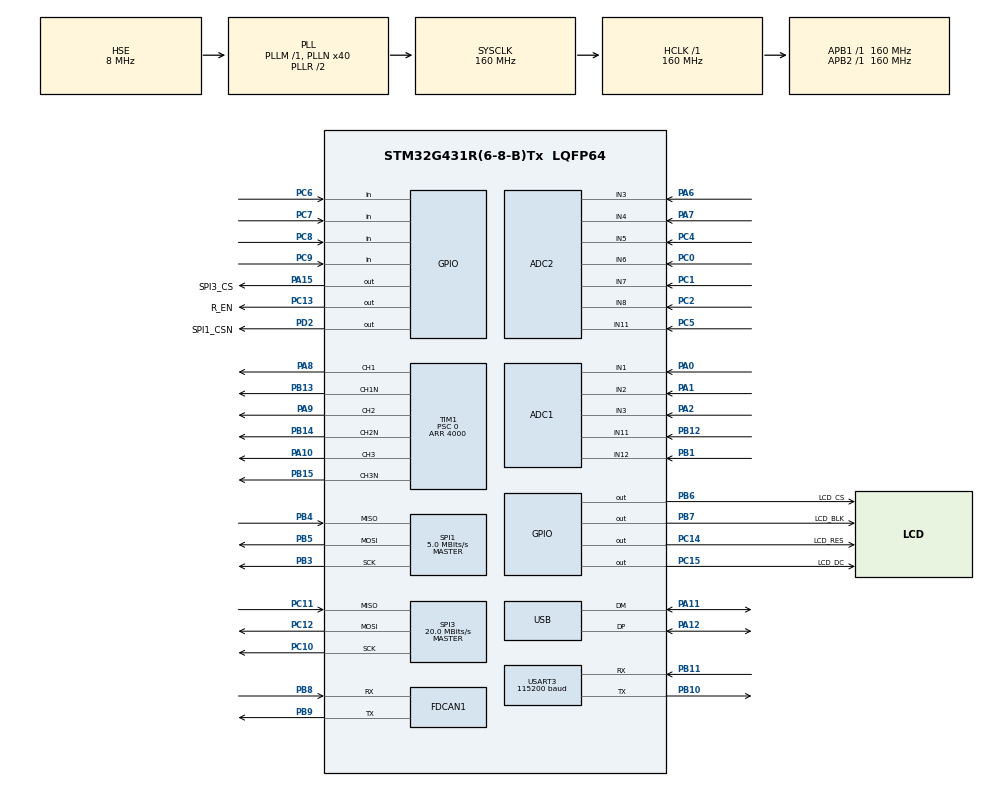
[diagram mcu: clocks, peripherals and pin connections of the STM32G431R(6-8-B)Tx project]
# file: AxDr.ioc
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ADC1.Channel-4\#ChannelRegularConversion=ADC_CHANNEL_11
ADC1.Channel-5\#ChannelRegularConversion=ADC_CHANNEL_12
ADC1.ContinuousConvMode=ENABLE
ADC1.DMAContinuousRequests=ENABLE
ADC1.EnableInjectedConversion=ENABLE
ADC1.EnableRegularConversion=ENABLE
ADC1.ExternalTrigInjecConv=ADC_EXTERNALTRIGINJEC_T1_CC4
ADC1.ExternalTrigInjecConvEdge=ADC_EXTERNALTRIGINJECCONV_EDGE_FALLING
ADC1.InjNumberOfConversion=3
ADC1.InjectedChannel-1\#ChannelInjectedConversion=ADC_CHANNEL_1
ADC1.InjectedChannel-2\#ChannelInjectedConversion=ADC_CHANNEL_2
ADC1.InjectedChannel-3\#ChannelInjectedConversion=ADC_CHANNEL_3
ADC1.InjectedOffsetNumber-1\#ChannelInjectedConversion=ADC_OFFSET_NONE
ADC1.InjectedOffsetNumber-2\#ChannelInjectedConversion=ADC_OFFSET_NONE
ADC1.InjectedOffsetNumber-3\#ChannelInjectedConversion=ADC_OFFSET_NONE
ADC1.InjectedRank-1\#ChannelInjectedConversion=1
ADC1.InjectedRank-2\#ChannelInjectedConversion=2
ADC1.InjectedRank-3\#ChannelInjectedConversion=3
ADC1.InjectedSamplingTime-1\#ChannelInjectedConversion=ADC_SAMPLETIME_47CYCLES_5
ADC1.InjectedSamplingTime-2\#ChannelInjectedConversion=ADC_SAMPLETIME_47CYCLES_5
ADC1.InjectedSamplingTime-3\#ChannelInjectedConversion=ADC_SAMPLETIME_47CYCLES_5
ADC1.NbrOfConversion=2
ADC1.NbrOfConversionFlag=1
ADC1.OffsetNumber-4\#ChannelRegularConversion=ADC_OFFSET_NONE
ADC1.OffsetNumber-5\#ChannelRegularConversion=ADC_OFFSET_NONE
ADC1.Rank-4\#ChannelRegularConversion=1
ADC1.Rank-5\#ChannelRegularConversion=2
ADC1.SamplingTime-4\#ChannelRegularConversion=ADC_SAMPLETIME_47CYCLES_5
ADC1.SamplingTime-5\#ChannelRegularConversion=ADC_SAMPLETIME_47CYCLES_5
ADC1.master=1
ADC2.Channel-11\#ChannelRegularConversion=ADC_CHANNEL_5
ADC2.Channel-12\#ChannelRegularConversion=ADC_CHANNEL_6
ADC2.Channel-13\#ChannelRegularConversion=ADC_CHANNEL_7
ADC2.Channel-14\#ChannelRegularConversion=ADC_CHANNEL_8
ADC2.ContinuousConvMode=ENABLE
ADC2.DMAContinuousRequests=ENABLE
ADC2.EnableInjectedConversion=ENABLE
ADC2.EnableRegularConversion=ENABLE
ADC2.ExternalTrigInjecConv=ADC_EXTERNALTRIGINJEC_T1_CC4
ADC2.ExternalTrigInjecConvEdge=ADC_EXTERNALTRIGINJECCONV_EDGE_FALLING
ADC2.InjNumberOfConversion=1
ADC2.InjectedChannel-1\#ChannelInjectedConversion=ADC_CHANNEL_11
ADC2.InjectedOffsetNumber-1\#ChannelInjectedConversion=ADC_OFFSET_NONE
ADC2.InjectedRank-1\#ChannelInjectedConversion=1
ADC2.InjectedSamplingTime-1\#ChannelInjectedConversion=ADC_SAMPLETIME_47CYCLES_5
ADC2.NbrOfConversion=4
ADC2.NbrOfConversionFlag=1
ADC2.OffsetNumber-11\#ChannelRegularConversion=ADC_OFFSET_NONE
ADC2.OffsetNumber-12\#ChannelRegularConversion=ADC_OFFSET_NONE
ADC2.OffsetNumber-13\#ChannelRegularConversion=ADC_OFFSET_NONE
ADC2.OffsetNumber-14\#ChannelRegularConversion=ADC_OFFSET_NONE
ADC2.Rank-11\#ChannelRegularConversion=1
ADC2.Rank-12\#ChannelRegularConversion=2
ADC2.Rank-13\#ChannelRegularConversion=3
ADC2.Rank-14\#ChannelRegularConversion=4
ADC2.SamplingTime-11\#ChannelRegularConversion=ADC_SAMPLETIME_47CYCLES_5
ADC2.SamplingTime-12\#ChannelRegularConversion=ADC_SAMPLETIME_47CYCLES_5
ADC2.SamplingTime-13\#ChannelRegularConversion=ADC_SAMPLETIME_47CYCLES_5
ADC2.SamplingTime-14\#ChannelRegularConversion=ADC_SAMPLETIME_47CYCLES_5
Dma.ADC1.3.Direction=DMA_PERIPH_TO_MEMORY
Dma.ADC1.3.EventEnable=DISABLE
Dma.ADC1.3.Instance=DMA1_Channel4
Dma.ADC1.3.MemDataAlignment=DMA_MDATAALIGN_HALFWORD
Dma.ADC1.3.MemInc=DMA_MINC_ENABLE
Dma.ADC1.3.Mode=DMA_CIRCULAR
Dma.ADC1.3.PeriphDataAlignment=DMA_PDATAALIGN_HALFWORD
Dma.ADC1.3.PeriphInc=DMA_PINC_DISABLE
Dma.ADC1.3.Polarity=HAL_DMAMUX_REQ_GEN_RISING
Dma.ADC1.3.Priority=DMA_PRIORITY_LOW
Dma.ADC1.3.RequestNumber=1
Dma.ADC1.3.SignalID=NONE
Dma.ADC1.3.SyncEnable=DISABLE
Dma.ADC1.3.SyncPolarity=HAL_DMAMUX_SYNC_NO_EVENT
Dma.ADC1.3.SyncRequestNumber=1
Dma.ADC1.3.SyncSignalID=NONE
Dma.ADC2.2.Direction=DMA_PERIPH_TO_MEMORY
Dma.ADC2.2.EventEnable=DISABLE
Dma.ADC2.2.Instance=DMA1_Channel3
Dma.ADC2.2.MemDataAlignment=DMA_MDATAALIGN_HALFWORD
Dma.ADC2.2.MemInc=DMA_MINC_ENABLE
Dma.ADC2.2.Mode=DMA_CIRCULAR
Dma.ADC2.2.PeriphDataAlignment=DMA_PDATAALIGN_HALFWORD
Dma.ADC2.2.PeriphInc=DMA_PINC_DISABLE
Dma.ADC2.2.Polarity=HAL_DMAMUX_REQ_GEN_RISING
Dma.ADC2.2.Priority=DMA_PRIORITY_LOW
Dma.ADC2.2.RequestNumber=1
Dma.ADC2.2.SignalID=NONE
Dma.ADC2.2.SyncEnable=DISABLE
Dma.ADC2.2.SyncPolarity=HAL_DMAMUX_SYNC_NO_EVENT
Dma.ADC2.2.SyncRequestNumber=1
Dma.ADC2.2.SyncSignalID=NONE
Dma.Request0=USART3_RX
Dma.Request1=USART3_TX
Dma.Request2=ADC2
Dma.Request3=ADC1
Dma.Request4=SPI1_RX
Dma.Request5=SPI1_TX
Dma.SPI1_RX.4.Direction=DMA_PERIPH_TO_MEMORY
Dma.SPI1_RX.4.EventEnable=DISABLE
Dma.SPI1_RX.4.Instance=DMA1_Channel5
Dma.SPI1_RX.4.MemDataAlignment=DMA_MDATAALIGN_BYTE
Dma.SPI1_RX.4.MemInc=DMA_MINC_ENABLE
Dma.SPI1_RX.4.Mode=DMA_CIRCULAR
Dma.SPI1_RX.4.PeriphDataAlignment=DMA_PDATAALIGN_BYTE
Dma.SPI1_RX.4.PeriphInc=DMA_PINC_DISABLE
Dma.SPI1_RX.4.Polarity=HAL_DMAMUX_REQ_GEN_RISING
Dma.SPI1_RX.4.Priority=DMA_PRIORITY_LOW
Dma.SPI1_RX.4.RequestNumber=1
Dma.SPI1_RX.4.SignalID=NONE
Dma.SPI1_RX.4.SyncEnable=DISABLE
Dma.SPI1_RX.4.SyncPolarity=HAL_DMAMUX_SYNC_NO_EVENT
Dma.SPI1_RX.4.SyncRequestNumber=1
Dma.SPI1_RX.4.SyncSignalID=NONE
Dma.SPI1_TX.5.Direction=DMA_MEMORY_TO_PERIPH
Dma.SPI1_TX.5.EventEnable=DISABLE
Dma.SPI1_TX.5.Instance=DMA1_Channel6
Dma.SPI1_TX.5.MemDataAlignment=DMA_MDATAALIGN_BYTE
Dma.SPI1_TX.5.MemInc=DMA_MINC_ENABLE
Dma.SPI1_TX.5.Mode=DMA_CIRCULAR
Dma.SPI1_TX.5.PeriphDataAlignment=DMA_PDATAALIGN_BYTE
Dma.SPI1_TX.5.PeriphInc=DMA_PINC_DISABLE
Dma.SPI1_TX.5.Polarity=HAL_DMAMUX_REQ_GEN_RISING
Dma.SPI1_TX.5.Priority=DMA_PRIORITY_LOW
Dma.SPI1_TX.5.RequestNumber=1
Dma.SPI1_TX.5.SignalID=NONE
Dma.SPI1_TX.5.SyncEnable=DISABLE
Dma.SPI1_TX.5.SyncPolarity=HAL_DMAMUX_SYNC_NO_EVENT
Dma.SPI1_TX.5.SyncRequestNumber=1
Dma.SPI1_TX.5.SyncSignalID=NONE
Dma.USART3_RX.0.Direction=DMA_PERIPH_TO_MEMORY
Dma.USART3_RX.0.EventEnable=DISABLE
Dma.USART3_RX.0.Instance=DMA1_Channel1
Dma.USART3_RX.0.MemDataAlignment=DMA_MDATAALIGN_BYTE
Dma.USART3_RX.0.MemInc=DMA_MINC_ENABLE
Dma.USART3_RX.0.Mode=DMA_NORMAL
Dma.USART3_RX.0.PeriphDataAlignment=DMA_PDATAALIGN_BYTE
Dma.USART3_RX.0.PeriphInc=DMA_PINC_DISABLE
Dma.USART3_RX.0.Polarity=HAL_DMAMUX_REQ_GEN_RISING
Dma.USART3_RX.0.Priority=DMA_PRIORITY_LOW
Dma.USART3_RX.0.RequestNumber=1
Dma.USART3_RX.0.SignalID=NONE
Dma.USART3_RX.0.SyncEnable=DISABLE
Dma.USART3_RX.0.SyncPolarity=HAL_DMAMUX_SYNC_NO_EVENT
Dma.USART3_RX.0.SyncRequestNumber=1
Dma.USART3_RX.0.SyncSignalID=NONE
Dma.USART3_TX.1.Direction=DMA_MEMORY_TO_PERIPH
Dma.USART3_TX.1.EventEnable=DISABLE
Dma.USART3_TX.1.Instance=DMA1_Channel2
Dma.USART3_TX.1.MemDataAlignment=DMA_MDATAALIGN_BYTE
Dma.USART3_TX.1.MemInc=DMA_MINC_ENABLE
Dma.USART3_TX.1.Mode=DMA_NORMAL
Dma.USART3_TX.1.PeriphDataAlignment=DMA_PDATAALIGN_BYTE
Dma.USART3_TX.1.PeriphInc=DMA_PINC_DISABLE
Dma.USART3_TX.1.Polarity=HAL_DMAMUX_REQ_GEN_RISING
Dma.USART3_TX.1.Priority=DMA_PRIORITY_LOW
Dma.USART3_TX.1.RequestNumber=1
Dma.USART3_TX.1.SignalID=NONE
Dma.USART3_TX.1.SyncEnable=DISABLE
Dma.USART3_TX.1.SyncPolarity=HAL_DMAMUX_SYNC_NO_EVENT
Dma.USART3_TX.1.SyncRequestNumber=1
Dma.USART3_TX.1.SyncSignalID=NONE
FDCAN1.AutoRetransmission=ENABLE
FDCAN1.CalculateBaudRateNominal=1000000
FDCAN1.CalculateTimeBitNominal=1000
FDCAN1.CalculateTimeQuantumNominal=12.5
FDCAN1.DataPrescaler=1
FDCAN1.DataSyncJumpWidth=1
FDCAN1.DataTimeSeg1=14
FDCAN1.DataTimeSeg2=1
FDCAN1.ExtFiltersNbr=8
FDCAN1.FrameFormat=FDCAN_FRAME_FD_BRS
FDCAN1.NominalPrescaler=1
FDCAN1.NominalSyncJumpWidth=20
FDCAN1.NominalTimeSeg1=59
FDCAN1.NominalTimeSeg2=20
FDCAN1.ProtocolException=DISABLE
FDCAN1.StdFiltersNbr=16
FDCAN1.TransmitPause=ENABLE
FREERTOS.Tasks01=defaultTask,24,128,StartDefaultTask,Default,NULL,Dynamic,NULL,NULL
Mcu.Family=STM32G4
Mcu.Name=STM32G431R(6-8-B)Tx
Mcu.Package=LQFP64
NVIC.ADC1_2_IRQn=true\:5\:0\:false\:false\:true\:true\:true\:true\:true
NVIC.DMA1_Channel1_IRQn=true\:5\:0\:false\:false\:true\:true\:false\:true\:true
NVIC.DMA1_Channel2_IRQn=true\:5\:0\:false\:false\:true\:true\:false\:true\:true
NVIC.DMA1_Channel3_IRQn=true\:5\:0\:false\:false\:true\:true\:false\:true\:true
NVIC.DMA1_Channel4_IRQn=true\:5\:0\:false\:false\:true\:true\:false\:true\:true
NVIC.DMA1_Channel5_IRQn=true\:5\:0\:false\:false\:true\:true\:false\:true\:true
NVIC.DMA1_Channel6_IRQn=true\:5\:0\:false\:false\:true\:true\:false\:true\:true
NVIC.FDCAN1_IT0_IRQn=true\:5\:0\:false\:false\:true\:true\:true\:true\:true
NVIC.FDCAN1_IT1_IRQn=true\:5\:0\:false\:false\:true\:true\:true\:true\:true
NVIC.PriorityGroup=NVIC_PRIORITYGROUP_4
NVIC.TIM1_UP_TIM16_IRQn=true\:5\:0\:false\:false\:true\:true\:true\:true\:true
NVIC.USART3_IRQn=true\:5\:0\:false\:false\:true\:true\:true\:true\:true
PA0.Mode=IN1-Single-Ended
PA0.Signal=ADC1_IN1
PA1.Mode=IN2-Single-Ended
PA1.Signal=ADC1_IN2
PA10.Signal=S_TIM1_CH3
PA11.Mode=Device
PA11.Signal=USB_DM
PA12.Mode=Device
PA12.Signal=USB_DP
PA13.Mode=Serial_Wire
PA13.Signal=SYS_JTMS-SWDIO
PA14.Mode=Serial_Wire
PA14.Signal=SYS_JTCK-SWCLK
PA15.GPIO_Label=SPI3_CS
PA15.GPIO_PuPd=GPIO_PULLUP
PA15.Signal=GPIO_Output
PA2.Mode=IN3-Single-Ended
PA2.Signal=ADC1_IN3
PA6.Mode=IN3-Single-Ended
PA6.Signal=ADC2_IN3
PA7.Mode=IN4-Single-Ended
PA7.Signal=ADC2_IN4
PA8.Signal=S_TIM1_CH1
PA9.Signal=S_TIM1_CH2
PB1.Mode=IN12-Single-Ended
PB1.Signal=ADC1_IN12
PB10.Mode=Asynchronous
PB10.Signal=USART3_TX
PB11.Mode=Asynchronous
PB11.Signal=USART3_RX
PB12.Mode=IN11-Single-Ended
PB12.Signal=ADC1_IN11
PB13.Mode=PWM Generation1 CH1 CH1N
PB13.Signal=TIM1_CH1N
PB14.Mode=PWM Generation2 CH2 CH2N
PB14.Signal=TIM1_CH2N
PB15.Mode=PWM Generation3 CH3 CH3N
PB15.Signal=TIM1_CH3N
PB3.Mode=Full_Duplex_Master
PB3.Signal=SPI1_SCK
PB4.Mode=Full_Duplex_Master
PB4.Signal=SPI1_MISO
PB5.Mode=Full_Duplex_Master
PB5.Signal=SPI1_MOSI
PB6.GPIO_Label=LCD_CS
PB6.GPIO_PuPd=GPIO_PULLDOWN
PB6.Signal=GPIO_Output
PB7.GPIO_Label=LCD_BLK
PB7.GPIO_PuPd=GPIO_PULLDOWN
PB7.Signal=GPIO_Output
PB8-BOOT0.Mode=FDCAN_Activate
PB8-BOOT0.Signal=FDCAN1_RX
PB9.Mode=FDCAN_Activate
PB9.Signal=FDCAN1_TX
PC0.Mode=IN6-Single-Ended
PC0.Signal=ADC2_IN6
PC1.Mode=IN7-Single-Ended
PC1.Signal=ADC2_IN7
PC10.Mode=Full_Duplex_Master
PC10.Signal=SPI3_SCK
PC11.Mode=Full_Duplex_Master
PC11.Signal=SPI3_MISO
PC12.Mode=Full_Duplex_Master
PC12.Signal=SPI3_MOSI
PC13.GPIO_Label=R_EN
PC13.Signal=GPIO_Output
PC14-OSC32_IN.GPIO_Label=LCD_RES
PC14-OSC32_IN.GPIO_PuPd=GPIO_PULLUP
PC14-OSC32_IN.PinState=GPIO_PIN_SET
PC14-OSC32_IN.Signal=GPIO_Output
PC15-OSC32_OUT.GPIO_Label=LCD_DC
PC15-OSC32_OUT.GPIO_PuPd=GPIO_PULLDOWN
PC15-OSC32_OUT.PinState=GPIO_PIN_SET
PC15-OSC32_OUT.Signal=GPIO_Output
PC2.Mode=IN8-Single-Ended
PC2.Signal=ADC2_IN8
PC4.Mode=IN5-Single-Ended
PC4.Signal=ADC2_IN5
PC5.Mode=IN11-Single-Ended
PC5.Signal=ADC2_IN11
PC6.GPIO_PuPd=GPIO_PULLUP
PC6.Signal=GPIO_Input
PC7.GPIO_PuPd=GPIO_PULLUP
PC7.Signal=GPIO_Input
PC8.GPIO_PuPd=GPIO_PULLUP
PC8.Signal=GPIO_Input
PC9.GPIO_PuPd=GPIO_PULLUP
PC9.Signal=GPIO_Input
PD2.GPIO_Label=SPI1_CSN
PD2.GPIO_PuPd=GPIO_PULLDOWN
PD2.Signal=GPIO_Output
PF0-OSC_IN.Mode=HSE-External-Oscillator
PF0-OSC_IN.Signal=RCC_OSC_IN
PF1-OSC_OUT.Mode=HSE-External-Oscillator
PF1-OSC_OUT.Signal=RCC_OSC_OUT
ProjectManager.HeapSize=0x200
ProjectManager.StackSize=0x400
ProjectManager.TargetToolchain=CMake
RCC.ADC12Freq_Value=160000000
RCC.ADC345Freq_Value=160000000
RCC.AHBFreq_Value=160000000
RCC.APB1Freq_Value=160000000
RCC.APB1TimFreq_Value=160000000
RCC.APB2Freq_Value=160000000
RCC.APB2TimFreq_Value=160000000
RCC.CK48CLockSelection=RCC_USBCLKSOURCE_HSI48
RCC.CortexFreq_Value=160000000
RCC.EXTERNAL_CLOCK_VALUE=12288000
RCC.FDCANCLockSelection=RCC_FDCANCLKSOURCE_PLL
RCC.HCLKFreq_Value=160000000
RCC.HSE_VALUE=8000000
RCC.HSI48_VALUE=48000000
RCC.HSI_VALUE=16000000
RCC.LSE_VALUE=32768
RCC.PLLN=40
RCC.PLLQ=RCC_PLLQ_DIV4
RCC.PLLSourceVirtual=RCC_PLLSOURCE_HSE
RCC.SYSCLKFreq_VALUE=160000000
RCC.SYSCLKSource=RCC_SYSCLKSOURCE_PLLCLK
RCC.USBFreq_Value=48000000
RCC.VCOOutputFreq_Value=320000000
SH.S_TIM1_CH1.0=TIM1_CH1,PWM Generation1 CH1 CH1N
SH.S_TIM1_CH2.0=TIM1_CH2,PWM Generation2 CH2 CH2N
SH.S_TIM1_CH3.0=TIM1_CH3,PWM Generation3 CH3 CH3N
SPI1.BaudRatePrescaler=SPI_BAUDRATEPRESCALER_32
SPI1.CLKPhase=SPI_PHASE_1EDGE
SPI1.CLKPolarity=SPI_POLARITY_HIGH
SPI1.CRCCalculation=SPI_CRCCALCULATION_DISABLE
SPI1.CalculateBaudRate=5.0 MBits/s
SPI1.DataSize=SPI_DATASIZE_8BIT
SPI1.Direction=SPI_DIRECTION_2LINES
SPI1.FirstBit=SPI_FIRSTBIT_MSB
SPI1.Mode=SPI_MODE_MASTER
SPI1.NSS=SPI_NSS_SOFT
SPI1.TIMode=SPI_TIMODE_DISABLE
SPI1.VirtualType=VM_MASTER
SPI3.BaudRatePrescaler=SPI_BAUDRATEPRESCALER_8
SPI3.CalculateBaudRate=20.0 MBits/s
SPI3.DataSize=SPI_DATASIZE_8BIT
SPI3.Direction=SPI_DIRECTION_2LINES
SPI3.Mode=SPI_MODE_MASTER
SPI3.VirtualType=VM_MASTER
TIM1.AutoReloadPreload=TIM_AUTORELOAD_PRELOAD_DISABLE
TIM1.AutomaticOutput=TIM_AUTOMATICOUTPUT_DISABLE
TIM1.Break2Filter=0
TIM1.Break2Polarity=TIM_BREAK2POLARITY_HIGH
TIM1.Break2State=TIM_BREAK2_DISABLE
TIM1.BreakFilter=0
TIM1.BreakPolarity=TIM_BREAKPOLARITY_HIGH
TIM1.BreakState=TIM_BREAK_DISABLE
TIM1.Channel-PWM\ Generation1\ CH1\ CH1N=TIM_CHANNEL_1
TIM1.Channel-PWM\ Generation2\ CH2\ CH2N=TIM_CHANNEL_2
TIM1.Channel-PWM\ Generation3\ CH3\ CH3N=TIM_CHANNEL_3
TIM1.Channel-PWM\ Generation4\ No\ Output=TIM_CHANNEL_4
TIM1.ClearInputSource=TIM_CLEARINPUTSOURCE_NONE
TIM1.ClockDivision=TIM_CLOCKDIVISION_DIV1
TIM1.CounterMode=TIM_COUNTERMODE_CENTERALIGNED2
TIM1.Dithering=Disable
TIM1.LockLevel=TIM_LOCKLEVEL_OFF
TIM1.OC4Preload_PWM=ENABLE
TIM1.OCFastMode_PWM-PWM\ Generation4\ No\ Output=TIM_OCFAST_DISABLE
TIM1.OCIdleState_4=TIM_OCIDLESTATE_RESET
TIM1.OCMode_PWM-PWM\ Generation4\ No\ Output=TIM_OCMODE_PWM1
TIM1.OCPolarity_4=TIM_OCPOLARITY_HIGH
TIM1.OffStateIDLEMode=TIM_OSSI_DISABLE
TIM1.PeriodNoDither=4000
TIM1.Prescaler=0
TIM1.PulseNoDither_4=0
TIM1.RepetitionCounter=0
TIM1.SourceBRK2COMP1=TIM_BREAKINPUTSOURCE_DISABLE
TIM1.SourceBRK2COMP2=TIM_BREAKINPUTSOURCE_DISABLE
TIM1.SourceBRK2COMP3=TIM_BREAKINPUTSOURCE_DISABLE
TIM1.SourceBRK2COMP4=TIM_BREAKINPUTSOURCE_DISABLE
TIM1.SourceBRK2DigInput=TIM_BREAKINPUTSOURCE_DISABLE
TIM1.SourceBRKCOMP1=TIM_BREAKINPUTSOURCE_DISABLE
TIM1.SourceBRKCOMP2=TIM_BREAKINPUTSOURCE_DISABLE
TIM1.SourceBRKCOMP3=TIM_BREAKINPUTSOURCE_DISABLE
TIM1.SourceBRKCOMP4=TIM_BREAKINPUTSOURCE_DISABLE
TIM1.SourceBRKDigInput=TIM_BREAKINPUTSOURCE_DISABLE
TIM1.TIM_MasterOutputTrigger=TIM_TRGO_RESET
TIM1.TIM_MasterOutputTrigger2=TIM_TRGO2_RESET
TIM1.TIM_MasterSlaveMode=TIM_MASTERSLAVEMODE_DISABLE
TIM3.Prescaler=0
USART3.BaudRate=115200
USART3.VirtualMode-Asynchronous=VM_ASYNC
USB.DeviceSpeed=PCD_SPEED_FULL
USB.Sof_enable=DISABLE
USB.battery_charging_enable=DISABLE
USB.low_power_enable=DISABLE
USB.lpm_enable=DISABLE
USB.phy_itface=PCD_PHY_EMBEDDED
VP_CRC_VS_CRC.Mode=CRC_Activate
VP_FREERTOS_VS_CMSIS_V2.Mode=CMSIS_V2
VP_SYS_VS_DBSignals.Mode=DisableDeadBatterySignals
VP_TIM1_VS_ClockSourceINT.Mode=Internal
VP_TIM1_VS_no_output4.Mode=PWM Generation4 No Output
VP_TIM3_VS_ClockSourceINT.Mode=Internal
board=custom

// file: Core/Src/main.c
/* USER CODE BEGIN Header */
/**
  ******************************************************************************
  * @file           : main.c
  * @brief          : Main program body
  ******************************************************************************
  * @attention
  *
  * Copyright (c) 2026 STMicroelectronics.
  * All rights reserved.
  *
  * This software is licensed under terms that can be found in the LICENSE file
  * in the root directory of this software component.
  * If no LICENSE file comes with this software, it is provided AS-IS.
  *
  ******************************************************************************
  */
/* USER CODE END Header */
#include "main.h"
#include "cmsis_os.h"
#include "adc.h"
#include "crc.h"
#include "dma.h"
#include "fdcan.h"
#include "spi.h"
#include "tim.h"
#include "usart.h"
#include "usb.h"
#include "gpio.h"

/* USER CODE BEGIN Includes */
#include "app_main.h"

/* USER CODE END Includes */

void SystemClock_Config(void);
void MX_FREERTOS_Init(void);

int main(void)
{

  /* MCU Configuration--------------------------------------------------------*/

  /* Reset of all peripherals, Initializes the Flash interface and the Systick. */
  HAL_Init();

  /* Configure the system clock */
  SystemClock_Config();

  /* Initialize all configured peripherals */
  MX_GPIO_Init();
  MX_DMA_Init();
  MX_SPI1_Init();
  MX_TIM1_Init();
  MX_TIM3_Init();
  MX_ADC1_Init();
  MX_ADC2_Init();
  MX_USART3_UART_Init();
  MX_FDCAN1_Init();
  MX_SPI3_Init();
  MX_USB_PCD_Init();
  MX_CRC_Init();
  /* USER CODE BEGIN 2 */
  /* Transfer control to application layer. app_main() is expected to run forever. */
  app_main();

  /* USER CODE END 2 */

  /* Init scheduler */
  osKernelInitialize();  /* Call init function for freertos objects (in cmsis_os2.c) */
  MX_FREERTOS_Init();

  /* Start scheduler */
  osKernelStart();

  /* We should never get here as control is now taken by the scheduler */

  /* Infinite loop */
  while (1)
  {

  }
}

void SystemClock_Config(void)
{
  RCC_OscInitTypeDef RCC_OscInitStruct = {0};
  RCC_ClkInitTypeDef RCC_ClkInitStruct = {0};

  /** Configure the main internal regulator output voltage
  */
  HAL_PWREx_ControlVoltageScaling(PWR_REGULATOR_VOLTAGE_SCALE1_BOOST);

  /** Initializes the RCC Oscillators according to the specified parameters
  * in the RCC_OscInitTypeDef structure.
  */
  RCC_OscInitStruct.OscillatorType = RCC_OSCILLATORTYPE_HSI48|RCC_OSCILLATORTYPE_HSE;
  RCC_OscInitStruct.HSEState = RCC_HSE_ON;
  RCC_OscInitStruct.HSI48State = RCC_HSI48_ON;
  RCC_OscInitStruct.PLL.PLLState = RCC_PLL_ON;
  RCC_OscInitStruct.PLL.PLLSource = RCC_PLLSOURCE_HSE;
  RCC_OscInitStruct.PLL.PLLM = RCC_PLLM_DIV1;
  RCC_OscInitStruct.PLL.PLLN = 40;
  RCC_OscInitStruct.PLL.PLLP = RCC_PLLP_DIV2;
  RCC_OscInitStruct.PLL.PLLQ = RCC_PLLQ_DIV4;
  RCC_OscInitStruct.PLL.PLLR = RCC_PLLR_DIV2;
  if (HAL_RCC_OscConfig(&RCC_OscInitStruct) != HAL_OK)
  {
    Error_Handler();
  }

  /** Initializes the CPU, AHB and APB buses clocks
  */
  RCC_ClkInitStruct.ClockType = RCC_CLOCKTYPE_HCLK|RCC_CLOCKTYPE_SYSCLK
                              |RCC_CLOCKTYPE_PCLK1|RCC_CLOCKTYPE_PCLK2;
  RCC_ClkInitStruct.SYSCLKSource = RCC_SYSCLKSOURCE_PLLCLK;
  RCC_ClkInitStruct.AHBCLKDivider = RCC_SYSCLK_DIV1;
  RCC_ClkInitStruct.APB1CLKDivider = RCC_HCLK_DIV1;
  RCC_ClkInitStruct.APB2CLKDivider = RCC_HCLK_DIV1;

  if (HAL_RCC_ClockConfig(&RCC_ClkInitStruct, FLASH_LATENCY_4) != HAL_OK)
  {
    Error_Handler();
  }
}

void Error_Handler(void)
{
  __disable_irq();
  while (1)
  {
  }
}

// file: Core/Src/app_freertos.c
/* USER CODE BEGIN Header */
/**
  ******************************************************************************
  * File Name          : app_freertos.c
  * Description        : Code for freertos applications
  ******************************************************************************
  * @attention
  *
  * Copyright (c) 2026 STMicroelectronics.
  * All rights reserved.
  *
  * This software is licensed under terms that can be found in the LICENSE file
  * in the root directory of this software component.
  * If no LICENSE file comes with this software, it is provided AS-IS.
  *
  ******************************************************************************
  */
/* USER CODE END Header */

#include "FreeRTOS.h"
#include "task.h"
#include "main.h"
#include "cmsis_os.h"

/* USER CODE BEGIN Includes */
#include "app_main.h"

/* USER CODE END Includes */

/* Definitions for defaultTask */
osThreadId_t defaultTaskHandle;
const osThreadAttr_t defaultTask_attributes = {
  .name = "defaultTask",
  .priority = (osPriority_t) osPriorityNormal,
  .stack_size = 128 * 4
};

void StartDefaultTask(void *argument);

void MX_FREERTOS_Init(void); /* (MISRA C 2004 rule 8.1) */

void MX_FREERTOS_Init(void) {

  /* Create the thread(s) */
  /* creation of defaultTask */
  defaultTaskHandle = osThreadNew(StartDefaultTask, NULL, &defaultTask_attributes);

}

void StartDefaultTask(void *argument)
{
  /* USER CODE BEGIN StartDefaultTask */
  /* Infinite loop */
  for(;;)
  {
    osDelay(1000);
  }
  /* USER CODE END StartDefaultTask */
}
